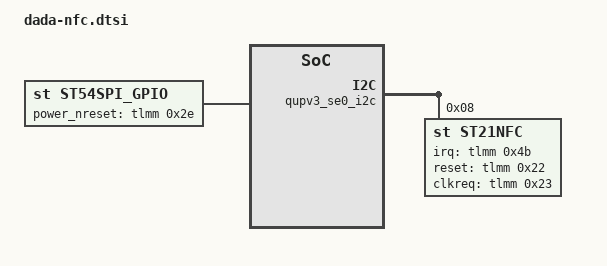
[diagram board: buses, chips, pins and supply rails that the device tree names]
// SPDX-License-Identifier: BSD-3-Clause
/*
 * Copyright (c) 2023-2024 Qualcomm Innovation Center, Inc. All rights reserved.
 * Copyright (c) 2025 The LineageOS Project
 */

&soc {
	st54spi_gpio {
		status = "ok";
		compatible = "st,st54spi_gpio";
		gpio-power_nreset = <&tlmm 0x2e 0x00>;
	};
};

&qupv3_se0_i2c {
	status = "ok";
	qcom,clk-freq-out = <0xf4240>;
	#address-cells = <0x01>;
	#size-cells = <0x00>;

	st21nfc: st21nfc@08 {
		compatible = "st,st21nfc";
		reg = <0x08>;
		irq-gpios = <&tlmm 0x4b 0x00>;
		reset-gpios = <&tlmm 0x22 0x00>;
		clkreq-gpios = <&tlmm 0x23 0x00>;
		interrupt-parent = <&tlmm>;
		interrupts = <0x4b 0x00>;
		interrupt-names = "nfc_irq";
		pinctrl-names = "nfc_active", "nfc_suspend";
		pinctrl-0 = <&nfc_int_active &nfc_enable_active>;
		pinctrl-1 = <&nfc_int_suspend &nfc_enable_suspend>;
	};
};
